# ATtiny841 register map
Vendor: Atmel
Registers are 8-bit, read-write, reset 0x0 unless marked. A register's access mark holds for its fields unless they carry their own. Offsets are from the block's base; lines under a group give offsets from that group; [hi:lo] are bit positions; {n}, {i} and the like mark numbered series; 'fields as' and 'values as' point back to an identical list; <NAME> marks a mode.

## Memory map
0x00000000 FUSE — Fuses
0x00000000 LOCKBIT — Lockbits
0x00000024 ADC — Analog-to-Digital Converter
0x0000002A AC — Analog Comparator
0x0000002E TC1 — Timer/Counter1, 16-bit
0x00000030 TC2 — Timer/Counter2, 16-bit
0x00000032 EXINT — External Interrupts
0x00000033 CPU — CPU Registers
0x00000036 PORTB — I/O Port
0x00000039 PORTA — I/O Port
0x0000003C EEPROM
0x00000041 WDT — Watchdog Timer
0x00000043 TC0 — Timer/Counter0, 8-bit, PWM
0x00000065 SPI — Serial Peripheral Interface
0x00000065 USART0 — USART
0x00000066 TOCPM — Timer/Counter Output Compare Pin
0x00000090 USART1 — USART
0x000000A0 TWI — Two Wire Serial Interface

## Interrupts
0 RESET (CPU) — External Pin, Power-on Reset, Brown-out Reset and Watchdog Reset
1 INT0 (CPU) — External Interrupt Request 0
2 PCINT0 (CPU) — Pin Change Interrupt Request 0
3 PCINT1 (CPU) — Pin Change Interrupt Request 1
4 WDT (CPU) — Watchdog Time-out Interrupt
5 TIMER1_CAPT (CPU) — Timer/Counter1 Capture Event
6 TIMER1_COMPA (CPU) — Timer/Counter1 Compare Match A
7 TIMER1_COMPB (CPU) — Timer/Counter1 Compare Match B
8 TIMER1_OVF (CPU) — Timer/Counter1 Overflow
9 TIMER0_COMPA (CPU) — TimerCounter0 Compare Match A
10 TIMER0_COMPB (CPU) — TimerCounter0 Compare Match B
11 TIMER0_OVF (CPU) — Timer/Couner0 Overflow
12 ANA_COMP0 (CPU) — Analog Comparator 0
13 ADC (CPU) — ADC Conversion Complete
14 EE_RDY (CPU) — EEPROM Ready
15 ANA_COMP1 (CPU) — Analog Comparator 1
16 TIMER2_CAPT (CPU) — Timer/Counter2 Capture Event
17 TIMER2_COMPA (CPU) — Timer/Counter2 Compare Match A
18 TIMER2_COMPB (CPU) — Timer/Counter2 Compare Match B
19 TIMER2_OVF (CPU) — Timer/Counter2 Overflow
20 SPI (CPU) — Serial Peripheral Interface
21 USART0_START (CPU)
22 USART0_RX (CPU) — USART0, Rx Complete
23 USART0_UDRE (CPU) — USART0 Data Register Empty
24 USART0_TX (CPU) — USART0, Tx Complete
25 USART1_START (CPU)
26 USART1_RX (CPU) — USART1, Rx Complete
27 USART1_UDRE (CPU) — USART1 Data Register Empty
28 USART1_TX (CPU) — USART1, Tx Complete
29 TWI_SLAVE (CPU) — Two-wire Serial Interface

## AC — Analog Comparator
Base 0x0000002A
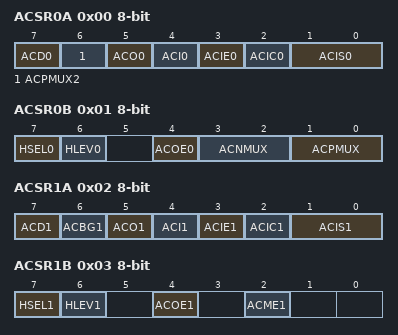
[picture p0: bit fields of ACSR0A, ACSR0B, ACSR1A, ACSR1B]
0x00 ACSR0A — Analog Comparator 0 Control And Status Register A
  [7] ACD0 — Analog Comparator 0 Disable
  [6] ACPMUX2 — Analog Comparator 0 Positive Input Multiplexer Bit 2
  [5] ACO0 — Analog Comparator 0 Output
  [4] ACI0 — Analog Comparator 0 Interrupt Flag
  [3] ACIE0 — Analog Comparator 0 Interrupt Enable
  [2] ACIC0 — Analog Comparator 0 Input Capture Enable
  [1:0] ACIS0 — Analog Comparator Interrupt Mode Select
    0=ON_TOGGLE (Interrupt on Toggle); 2=ON_FALLING_EDGE (Interrupt on Falling Edge); 3=ON_RISING_EDGE (Interrupt on Rising Edge)
0x01 ACSR0B — Analog Comparator 0 Control And Status Register B
  [7] HSEL0 — Analog Comparator 0 Hysteresis Select
  [6] HLEV0 — Analog Comparator 0 Hysteresis Level
  [4] ACOE0 — Analog Comparator 0 Output Pin Enable
  [3:2] ACNMUX — Analog Comparator 0 Negative Input Multiplexer
  [1:0] ACPMUX — Analog Comparator 0 Positive Input Multiplexer Bits 1:0
0x02 ACSR1A — Analog Comparator 1 Control And Status Register A
  [7] ACD1 — Analog Comparator 1 Disable
  [6] ACBG1 — Analog Comparator 1 Bandgap Select
  [5] ACO1 — Analog Comparator 1 Output
  [4] ACI1 — Analog Comparator 1 Interrupt Flag
  [3] ACIE1 — Analog Comparator 1 Interrupt Enable
  [2] ACIC1 — Analog Comparator 1 Input Capture Enable
  [1:0] ACIS1 — Analog Comparator Interrupt Mode Select
    values as ACSR0A.ACIS0
0x03 ACSR1B — Analog Comparator 1 Control And Status Register B
  [7] HSEL1 — Analog Comparator 1 Hysteresis Select
  [6] HLEV1 — Analog Comparator 1 Hysteresis Level
  [4] ACOE1 — Analog Comparator 1 Output Pin Enable
  [2] ACME1 — Analog Comparator 1 Multiplexer Enable
